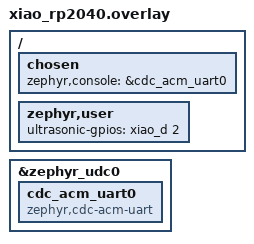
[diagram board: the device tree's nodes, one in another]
/*
 * RP2040 uses firmware-provided USB CDC ACM for console and 1200-baud UF2 entry.
 * The default Grove signal pin is D2; create/set-pins can override it.
 *
 * RP2040 使用固件提供的 USB CDC ACM 作为控制台和 1200 baud UF2 入口。
 * Grove 信号默认引脚为 D2；create/set-pins 可覆盖它。
 */

/ {
	chosen {
		zephyr,console = &cdc_acm_uart0;
	};
	zephyr,user {
		ultrasonic-gpios = <&xiao_d 2 GPIO_ACTIVE_HIGH>;
	};
};

&zephyr_udc0 {
	cdc_acm_uart0: cdc_acm_uart0 {
		compatible = "zephyr,cdc-acm-uart";
	};
};
